# AT32F403A register map
Vendor: Keil; Series: AT32F403A; File version: 1.0
CPU: CM4 r0p1, little endian, no MPU, FPU, 4 interrupt priority bits
Registers are 32-bit, read-write, reset 0x0 unless marked. A register's access mark holds for its fields unless they carry their own. Offsets are from the block's base; [hi:lo] are bit positions; {n}, {i} and the like mark numbered series.

## WWDT — Window watchdog
Base 0x40002C00
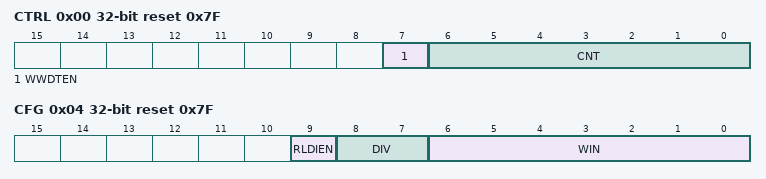
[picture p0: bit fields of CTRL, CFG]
0x00 CTRL reset 0x7F — Control register
  [7] WWDTEN write-1-sets — Window watchdog enable
    on read: 0=Disabled; 1=Enabled | on write: 1=Enable
  [6:0] CNT — Decrement counter
0x04 CFG reset 0x7F — Configuration register
  [9] RLDIEN — Reload counter interrupt
    on read: 0=Disabled; 1=Enabled | on write: 0=Disable; 1=Enable
  [8:7] DIV — Clock division value
    0=PCLK1 divided by 4096; 1=PCLK1 divided by 8192; 2=PCLK1 divided by 16384; 3=PCLK1 divided by 32768
  [6:0] WIN — Window value
0x08 STS — Status register
  [0] RLDF write-0-clears — Reload counter interrupt flag
    on read: 0=NotReached (Downcounter doesn't reached 0x40); 1=Reached (Downcounter reached 0x40) | on write: 0=Clear flag

## ACC — HICK Auto Clock Calibration
Base 0x40015800
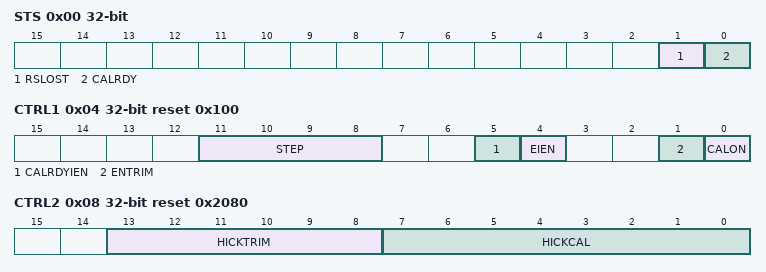
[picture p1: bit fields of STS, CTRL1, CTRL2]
0x00 STS ro — status register
  [1] RSLOST rw — Reference Signal Lost
    0=NotLost (Reference Signal is not lost); 1=Lost (Reference Signal is lost)
  [0] CALRDY rw — Internal high-speed clock calibration ready
    0=NotReady (Interal 8MHz oscillator calibration is not ready); 1=Ready (Interal 8MHz oscillator calibration is ready)
0x04 CTRL1 reset 0x100 — control register 1
  [11:8] STEP — Calibrated step
  [5] CALRDYIEN — CALRDY interrupt enable
    on read: 0=Disabled (Interrupt generation disabled); 1=Enabled (ACC interrupt is generated when CALRDY=1 in the ACC_STS register) | on write: 0=Disable (Interrupt generation disabled); 1=Enable (ACC interrupt is generated when CALRDY=1 in the ACC_STS register)
  [4] EIEN — RSLOST error interrupt enable
    on read: 0=Disabled (Interrupt generation disabled); 1=Enabled (ACC interrupt is generated when RSLOST=1 in the ACC_STS register) | on write: 0=Disable (Interrupt generation disabled); 1=Enable (ACC interrupt is generated when RSLOST=1 in the ACC_STS register)
  [1] ENTRIM — Enable trim
    0=HICKCAL (HICKCAL is calibrated); 1=HICKTRIM (HICKTRIM is calibrated)
  [0] CALON — Calibration on
    on read: 0=Disabled (Calibration disabled); 1=Enabled (Calibration enabled, and starts searching for a pulse on the USB_SOF) | on write: 0=Disable (Calibration disabled); 1=Enable (Calibration enabled, and starts searching for a pulse on the USB_SOF)
0x08 CTRL2 reset 0x2080 — control register 2
  [13:8] HICKTRIM ro — Internal high-speed auto clock trimming
  [7:0] HICKCAL ro — Internal high-speed auto clock calibration
0x0C C1 reset 0x1F2C — compare value 1
  [15:0] C1 — Compare 1
0x10 C2 reset 0x1F40 — compare value 2
  [15:0] C2 — Compare 2
0x14 C3 reset 0x1F54 — compare value 3
  [15:0] C3 — Compare 3

## TMR6 — Basic timer
Base 0x40001000
Same registers: TMR7 0x40001400
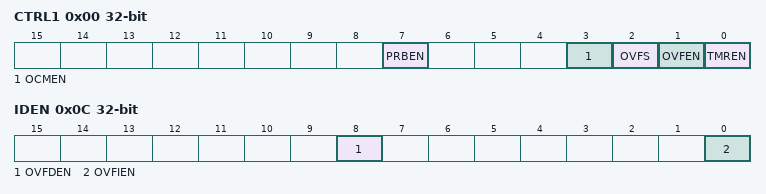
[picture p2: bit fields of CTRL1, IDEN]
0x00 CTRL1 — Control register 1
  [7] PRBEN — Period buffer enable
    on read: 0=Disabled (Period buffer is disabled); 1=Enabled (Period buffer is enabled) | on write: 0=Disable (Period buffer disable); 1=Enable (Period buffer enable)
  [3] OCMEN — One cycle mode enable
    0=Continuous (The counter does not stop at an update event); 1=OneCycle (The counter stops at an update event)
  [2] OVFS — Overflow event source
    0=Any (Counter overflow, setting the OVFSWTR bit or overflow event generated by slave timer controller); 1=Counter (Only counter overflow generates an overflow event)
  [1] OVFEN — Overflow event enable
    on read: 0=Enabled (Overflow is enabled); 1=Disabled (Overflow is disabled) | on write: 0=Enable (Overflow enable); 1=Disable (Overflow disable)
  [0] TMREN — TMR enable
    on read: 0=Disabled (Timer is disabled); 1=Enabled (Timer is enabled) | on write: 0=Disable (Timer disable); 1=Enable (Timer enable)
0x04 CTRL2 — Control register 2
  [6:4] PTOS — Primary TMR output selection
    0=Reset; 1=Enable; 2=Update
0x0C IDEN — Interrupt/DMA enable register
  [8] OVFDEN — Overflow DMA request enable
    on read: 0=Disabled (Overflow event DMA request is disabled); 1=Enabled (Overflow event DMA request is enabled) | on write: 0=Disable (Overflow event DMA request disable); 1=Enable (Overflow event DMA request enable)
  [0] OVFIEN — Overflow interrupt enable
    on read: 0=Disabled (Overflow interrupt is disabled); 1=Enabled (Overflow interrupt is enabled) | on write: 0=Disable (Overflow interrupt disable); 1=Enable (Overflow interrupt enable)
0x10 ISTS — Interrupt status register
  [0] OVFIF write-0-clears — Overflow interrupt flag
    on read: 0=No overflow event occurs; 1=Overflow (An overflow event is generated) | on write: 0=Clear (Overflow interrupt flag clear)
0x14 SWEVT — Software event register
  [0] OVFSWTR write-1-sets — Overflow event triggered by software
    on write: 1=OverflowEvent (Generate an overflow event)
0x24 CVAL — Counter value
  [15:0] CVAL
0x28 DIV — Divider value
  [15:0] DIV — The counter clock frequency Fck_cnt = Ftmr_clk /({value}+1).
0x2C PR reset 0xFFFF — Period value
  [15:0] PR
